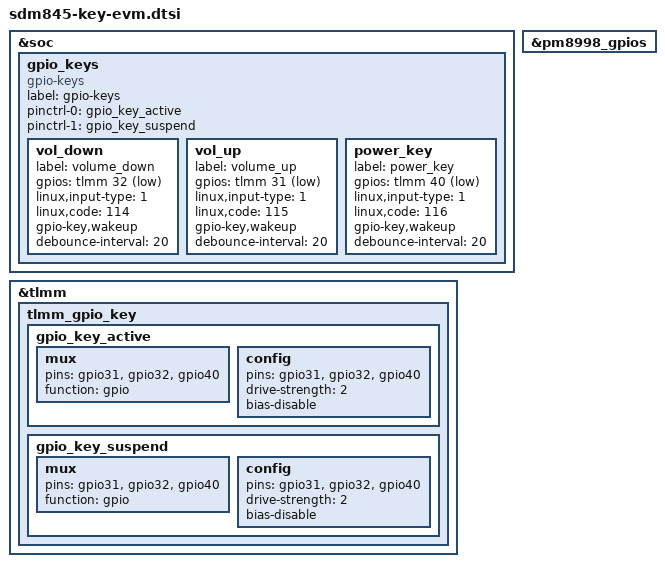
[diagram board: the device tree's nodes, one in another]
&soc {
	/delete-node/ gpio_keys;
	gpio_keys {
		compatible = "gpio-keys";
		label = "gpio-keys";

		pinctrl-names = "tlmm_gpio_key_active","tlmm_gpio_key_suspend";
		pinctrl-0 = <&gpio_key_active>;
		pinctrl-1 = <&gpio_key_suspend>;

		vol_down {
			label = "volume_down";
			gpios = <&tlmm 32 GPIO_ACTIVE_LOW>;
			linux,input-type = <1>;
			linux,code = <114>;
			gpio-key,wakeup;
			debounce-interval = <20>;
		};

		vol_up {
			label = "volume_up";
			gpios = <&tlmm 31 GPIO_ACTIVE_LOW>;
			linux,input-type = <1>;
			linux,code = <115>;
			gpio-key,wakeup;
			debounce-interval = <20>;
		};

		power_key {
			label = "power_key";
			gpios = <&tlmm 40 GPIO_ACTIVE_LOW>;
			linux,input-type = <1>;
			linux,code = <116>;
			gpio-key,wakeup;
			debounce-interval = <20>;
		};
	};
};

&tlmm {
	tlmm_gpio_key {
		gpio_key_active: gpio_key_active {
			mux {
				pins = "gpio31", "gpio32", "gpio40";
				function = "gpio";
			};
			config {
				pins = "gpio31", "gpio32", "gpio40";
				drive-strength = <2>;
				bias-disable;
			};
		};
		gpio_key_suspend: gpio_key_suspend {
			mux {
				pins = "gpio31", "gpio32", "gpio40";
				function = "gpio";
			};
			config {
				pins = "gpio31", "gpio32", "gpio40";
				drive-strength = <2>;
				bias-disable;
			};
		};
	};
};

&pm8998_gpios {
	/delete-node/ key_home;
	/delete-node/ key_vol_up;
	/delete-node/ key_cam_snapshot;
	/delete-node/ key_cam_focus;
};
